# SAM9X60 device description
Architecture: ARM926EJS; Family: SAM9; Series: SAM9X
Registers are 32-bit, read-write, no defined reset value unless marked. A register's access mark holds for its fields unless they carry their own. Offsets are from the block's base; [hi:lo] are bit positions; lines under a group give offsets from that group; {n}, {i} and the like mark numbered series; 'fields as' and 'values as' point back to an identical list; <NAME> marks a mode.

## RTC — Real-time Clock
Instances: RTC 0xFFFFFEA8
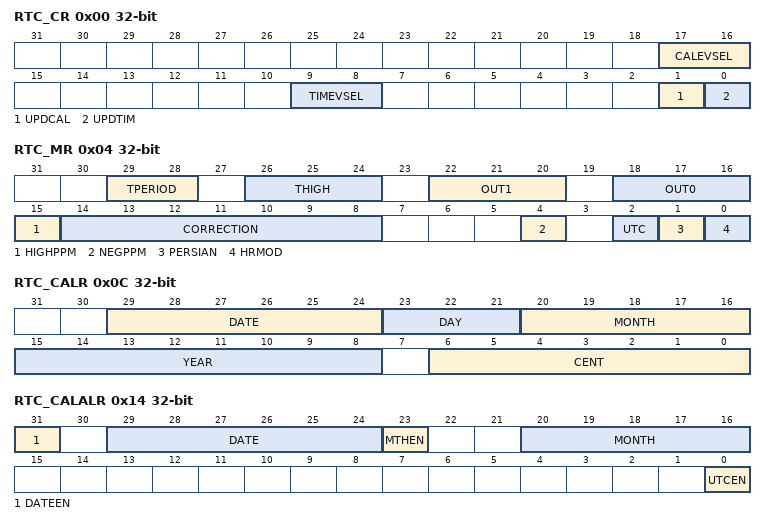
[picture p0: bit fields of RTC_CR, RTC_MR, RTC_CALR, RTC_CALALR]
0x00 RTC_CR — Control Register
  [17:16] CALEVSEL — Calendar Event Selection
    0=WEEK (Week change (every Monday at time 00:00:00)); 1=MONTH (Month change (every 01 of each month at time 00:00:00)); 2=YEAR (Year change (every January 1 at time 00:00:00))
  [9:8] TIMEVSEL — Time Event Selection
    0=MINUTE (Minute change); 1=HOUR (Hour change); 2=MIDNIGHT (Every day at midnight); 3=NOON (Every day at noon)
  [1] UPDCAL — Update Request Calendar Register
  [0] UPDTIM — Update Request Time Register
0x04 RTC_MR — Mode Register
  [29:28] TPERIOD — Period of the Output Pulse
    0=P_1S (1 second); 1=P_500MS (500 ms); 2=P_250MS (250 ms); 3=P_125MS (125 ms)
  [26:24] THIGH — High Duration of the Output Pulse
    0=H_31MS (31.2 ms); 1=H_16MS (15.6 ms); 2=H_4MS (3.91 ms); 3=H_976US (976 us); 4=H_488US (488 us); 5=H_122US (122 us); 6=H_30US (30.5 us); 7=H_15US (15.2 us)
  [22:20] OUT1 — ADC Last Channel Trigger Event Source Selection
    0=NO_WAVE (No waveform, stuck at '0'); 1=FREQ1HZ (1 Hz square wave); 2=FREQ32HZ (32 Hz square wave); 3=FREQ64HZ (64 Hz square wave); 4=FREQ512HZ (512 Hz square wave); 5=ALARM_TOGGLE (Output toggles when alarm flag rises); 6=ALARM_FLAG (Output is a copy of the alarm flag); 7=PROG_PULSE (Duty cycle programmable pulse)
  [18:16] OUT0 — All ADC Channel Trigger Event Source Selection
    values as OUT1
  [15] HIGHPPM — HIGH PPM Correction
  [14:8] CORRECTION — Slow Clock Correction
  [4] NEGPPM — NEGative PPM Correction
  [2] UTC — UTC Time Format
  [1] PERSIAN — PERSIAN Calendar
  [0] HRMOD — 12-/24-hour Mode
0x08 RTC_TIMR — Time Register
  [22] AMPM <DEFAULT> — Ante Meridiem Post Meridiem Indicator
  [21:16] HOUR <DEFAULT> — Current Hour
  [14:8] MIN <DEFAULT> — Current Minute
  [6:0] SEC <DEFAULT> — Current Second
  [31:0] UTC_TIME <UTC_MODE> — Current UTC Time
0x0C RTC_CALR — Calendar Register
  [29:24] DATE — Current Day in Current Month
  [23:21] DAY — Current Day in Current Week
  [20:16] MONTH — Current Month
  [15:8] YEAR — Current Year
  [6:0] CENT — Current Century
0x10 RTC_TIMALR — Time Alarm Register
  [23] HOUREN <DEFAULT> — Hour Alarm Enable
  [22] AMPM <DEFAULT> — AM/PM Indicator
  [21:16] HOUR <DEFAULT> — Hour Alarm
  [15] MINEN <DEFAULT> — Minute Alarm Enable
  [14:8] MIN <DEFAULT> — Minute Alarm
  [7] SECEN <DEFAULT> — Second Alarm Enable
  [6:0] SEC <DEFAULT> — Second Alarm
  [31:0] UTC_TIME <UTC_MODE> — UTC_TIME Alarm
0x14 RTC_CALALR — Calendar Alarm Register
  [31] DATEEN <DEFAULT> — Date Alarm Enable
  [29:24] DATE <DEFAULT> — Date Alarm
  [23] MTHEN <DEFAULT> — Month Alarm Enable
  [20:16] MONTH <DEFAULT> — Month Alarm
  [0] UTCEN <UTC_MODE> — UTC Alarm Enable
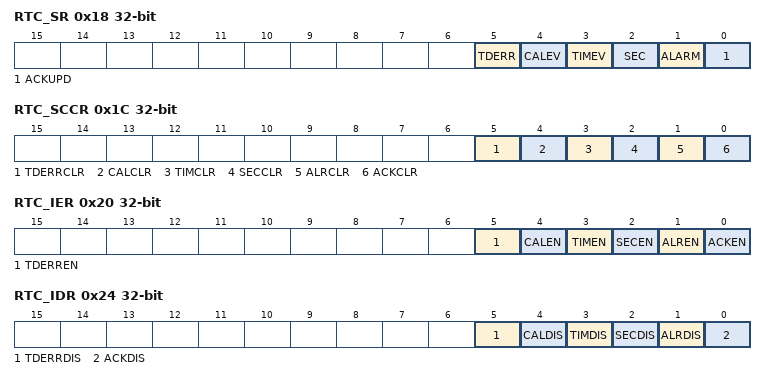
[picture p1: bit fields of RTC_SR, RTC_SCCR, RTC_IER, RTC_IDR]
0x18 RTC_SR ro — Status Register
  [5] TDERR — Time and/or Date Free Running Error
    0=CORRECT (The internal free running counters are carrying valid values since the last read of the Status Register (RTC_SR).); 1=ERR_TIMEDATE (The internal free running counters have been corrupted (invalid date or time, non-BCD values) since the last read and/or they are still invalid.)
  [4] CALEV — Calendar Event
    0=NO_CALEVENT (No calendar event has occurred since the last clear.); 1=CALEVENT (At least one calendar event has occurred since the last clear.)
  [3] TIMEV — Time Event
    0=NO_TIMEVENT (No time event has occurred since the last clear.); 1=TIMEVENT (At least one time event has occurred since the last clear.)
  [2] SEC — Second Event
    0=NO_SECEVENT (No second event has occurred since the last clear.); 1=SECEVENT (At least one second event has occurred since the last clear.)
  [1] ALARM — Alarm Flag
    0=NO_ALARMEVENT (No alarm matching condition occurred.); 1=ALARMEVENT (An alarm matching condition has occurred.)
  [0] ACKUPD — Acknowledge for Update
    0=FREERUN (Time and calendar registers cannot be updated.); 1=UPDATE (Time and calendar registers can be updated.)
0x1C RTC_SCCR wo — Status Clear Command Register
  [5] TDERRCLR — Time and/or Date Free Running Error Clear
  [4] CALCLR — Calendar Clear
  [3] TIMCLR — Time Clear
  [2] SECCLR — Second Clear
  [1] ALRCLR — Alarm Clear
  [0] ACKCLR — Acknowledge Clear
0x20 RTC_IER wo — Interrupt Enable Register
  [5] TDERREN — Time and/or Date Error Interrupt Enable
  [4] CALEN — Calendar Event Interrupt Enable
  [3] TIMEN — Time Event Interrupt Enable
  [2] SECEN — Second Event Interrupt Enable
  [1] ALREN — Alarm Interrupt Enable
  [0] ACKEN — Acknowledge Update Interrupt Enable
0x24 RTC_IDR wo — Interrupt Disable Register
  [5] TDERRDIS — Time and/or Date Error Interrupt Disable
  [4] CALDIS — Calendar Event Interrupt Disable
  [3] TIMDIS — Time Event Interrupt Disable
  [2] SECDIS — Second Event Interrupt Disable
  [1] ALRDIS — Alarm Interrupt Disable
  [0] ACKDIS — Acknowledge Update Interrupt Disable
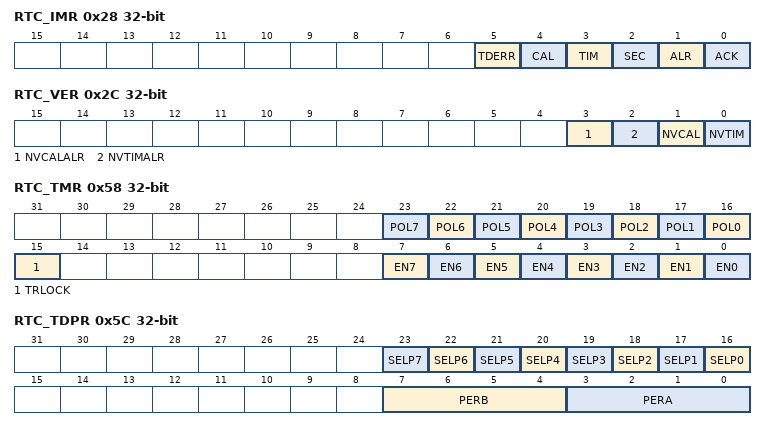
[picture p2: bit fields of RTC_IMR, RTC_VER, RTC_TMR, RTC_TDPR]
0x28 RTC_IMR ro — Interrupt Mask Register
  [5] TDERR — Time and/or Date Error Mask
  [4] CAL — Calendar Event Interrupt Mask
  [3] TIM — Time Event Interrupt Mask
  [2] SEC — Second Event Interrupt Mask
  [1] ALR — Alarm Interrupt Mask
  [0] ACK — Acknowledge Update Interrupt Mask
0x2C RTC_VER ro — Valid Entry Register
  [3] NVCALALR — Non-valid Calendar Alarm
  [2] NVTIMALR — Non-valid Time Alarm
  [1] NVCAL — Non-valid Calendar
  [0] NVTIM — Non-valid Time
0x58 RTC_TMR — Tamper Mode register
  [n+16] POL{n} (n=0..7) — WKUPx+1 Polarity
    0=LOW (If the source of tamper remains low for a debounce period, a tamper event is generated.); 1=HIGH (If the source of tamper remains high for a debounce period, a tamper event is generated.)
  [15] TRLOCK — Tamper Registers Lock (Write-once, cleared by VDDCORE reset)
    0=UNLOCKED (RTC_TMR and RTC_TDPR can be written.); 1=LOCKED (RTC_TMR and RTC_TDPR cannot be written until the next VDDCORE domain reset.)
  [n] EN{n} (n=0..7) — WKUPx+1 Tamper Source Enable
    0=DISABLE (WKUP pin index x+1 is not enabled as a source of tamper.); 1=ENABLE (WKUP pin index x+1 is enabled as a source of tamper.)
0x5C RTC_TDPR — Tamper Debounce Period register
  [n+16] SELP{n} (n=0..7) — WKUPx+1 Debounce Period Selection
    0=SEL_PA (WKUP pin index x+1 is debounced with PERA period.); 1=SEL_PB (WKUP pin index x+1 is debounced with PERB period.)
  [7:4] PERB — Debounce Period B
    0=MD_SCLK_2 (The source of tamper must remain active for at least 2 monitoring-domain slow clock cycles to generate a tamper event.); 1=MD_SCLK_4 (The source of tamper must remain active for at least 4 monitoring-domain slow clock cycles to generate a tamper event.); 2=MD_SCLK_8 (The source of tamper must remain active for at least 8 monitoring-domain slow clock cycles to generate a tamper event.); 3=MD_SCLK_16 (The source of tamper must remain active for at least 16 monitoring-domain slow clock cycles to generate a tamper event.); 4=MD_SCLK_32 (The source of tamper must remain active for at least 32 monitoring-domain slow clock cycles to generate a tamper event.); 5=MD_SCLK_64 (The source of tamper must remain active for at least 64 monitoring-domain slow clock cycles to generate a tamper event.); 6=MD_SCLK_128 (The source of tamper must remain active for at least 128 monitoring-domain slow clock cycles to generate a tamper event.); 7=MD_SCLK_256 (The source of tamper must remain active for at least 256 monitoring-domain slow clock cycles to generate a tamper event.)
  [3:0] PERA — Debounce Period A
    values as PERB
{0xB0+0xC*i} RTC_TS[{i}] (i=0..1) group
  0x00 RTC_TSTR ro — TimeStamp Time Register 0
    [31] BACKUP <DEFAULT> — System Mode of the Tamper (cleared by reading RTC_TSSR0)
    [27:24] TEVCNT <DEFAULT> — Tamper Events Counter (cleared by reading RTC_TSSR0)
    [22] AMPM <DEFAULT> — AM/PM Indicator of the Tamper (cleared by reading RTC_TSSR0)
    [21:16] HOUR <DEFAULT> — Hours of the Tamper (cleared by reading RTC_TSSR0)
    [14:8] MIN <DEFAULT> — Minutes of the Tamper (cleared by reading RTC_TSSR0)
    [6:0] SEC <DEFAULT> — Seconds of the Tamper (cleared by reading RTC_TSSR0)
    [31] BACKUP <UTC_MODE> — System Mode of the Tamper (cleared by reading RTC_TSSR0)
    [27:24] TEVCNT <UTC_MODE> — Tamper Events Counter (cleared by reading RTC_TSSR0)
  0x04 RTC_TSDR ro — TimeStamp Date Register 0
    [29:24] DATE <DEFAULT> — Date of the Tamper (cleared by reading RTC_TSSRx)
    [23:21] DAY <DEFAULT> — Day of the Tamper (cleared by reading RTC_TSSRx)
    [20:16] MONTH <DEFAULT> — Month of the Tamper (cleared by reading RTC_TSSRx)
    [15:8] YEAR <DEFAULT> — Year of the Tamper (cleared by reading RTC_TSSRx)
    [6:0] CENT <DEFAULT> — Century of the Tamper (cleared by reading RTC_TSSRx)
    [31:0] UTC_TIME <UTC_MODE> — Time of the Tamper (UTC format)
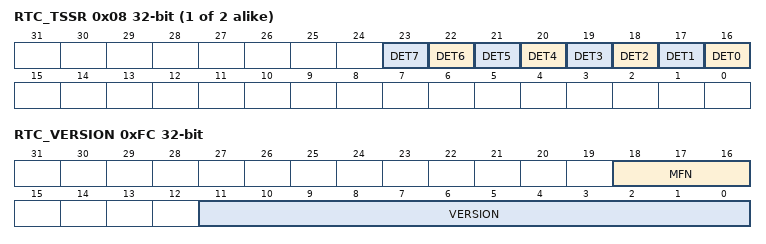
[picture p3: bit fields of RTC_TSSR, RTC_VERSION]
  0x08 RTC_TSSR ro — TimeStamp Source Register 0
    [n+16] DET{n} (n=0..7) — Tamper Detection on VDDCORE WKUP[8:1] (cleared on read)
0xFC RTC_VERSION ro — Version Register
  [18:16] MFN — Metal Fix Number
  [11:0] VERSION — Version of the Hardware Module
